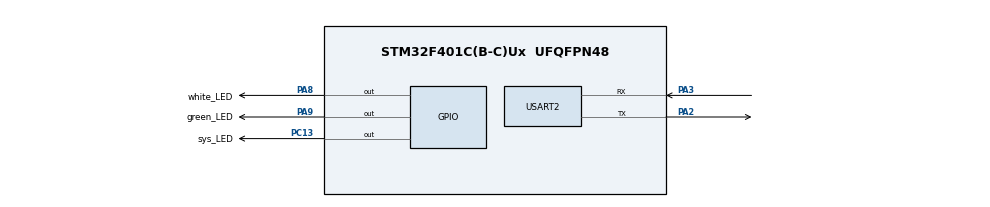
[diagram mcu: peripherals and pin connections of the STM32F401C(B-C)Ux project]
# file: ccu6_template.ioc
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FREERTOS.INCLUDE_pcTaskGetTaskName=1
FREERTOS.INCLUDE_uxTaskGetStackHighWaterMark2=1
FREERTOS.INCLUDE_vTaskCleanUpResources=1
FREERTOS.INCLUDE_xEventGroupSetBitFromISR=1
FREERTOS.INCLUDE_xSemaphoreGetMutexHolder=1
FREERTOS.INCLUDE_xTaskAbortDelay=1
FREERTOS.INCLUDE_xTaskGetHandle=1
FREERTOS.Tasks01=defaultTask,24,128,StartDefaultTask,Default,NULL,Dynamic,NULL,NULL
Mcu.Family=STM32F4
Mcu.Name=STM32F401C(B-C)Ux
Mcu.Package=UFQFPN48
NVIC.PriorityGroup=NVIC_PRIORITYGROUP_4
NVIC.TIM1_TRG_COM_TIM11_IRQn=true\:15\:0\:false\:false\:true\:false\:false\:true\:true
NVIC.TimeBase=TIM1_TRG_COM_TIM11_IRQn
NVIC.TimeBaseIP=TIM11
NVIC.USART2_IRQn=true\:5\:0\:false\:false\:true\:true\:true\:true\:true
PA13.Mode=Serial_Wire
PA13.Signal=SYS_JTMS-SWDIO
PA14.Mode=Serial_Wire
PA14.Signal=SYS_JTCK-SWCLK
PA2.Mode=Asynchronous
PA2.Signal=USART2_TX
PA3.Mode=Asynchronous
PA3.Signal=USART2_RX
PA8.GPIO_Label=white_LED
PA8.GPIO_ModeDefaultOutputPP=GPIO_MODE_OUTPUT_OD
PA8.GPIO_PuPd=GPIO_NOPULL
PA8.GPIO_Speed=GPIO_SPEED_FREQ_HIGH
PA8.PinState=GPIO_PIN_SET
PA8.Signal=GPIO_Output
PA9.GPIO_Label=green_LED
PA9.GPIO_ModeDefaultOutputPP=GPIO_MODE_OUTPUT_OD
PA9.GPIO_PuPd=GPIO_NOPULL
PA9.GPIO_Speed=GPIO_SPEED_FREQ_VERY_HIGH
PA9.PinState=GPIO_PIN_SET
PA9.Signal=GPIO_Output
PC13-ANTI_TAMP.GPIO_Label=sys_LED
PC13-ANTI_TAMP.GPIO_ModeDefaultOutputPP=GPIO_MODE_OUTPUT_OD
PC13-ANTI_TAMP.GPIO_PuPd=GPIO_NOPULL
PC13-ANTI_TAMP.PinState=GPIO_PIN_SET
PC13-ANTI_TAMP.Signal=GPIO_Output
PC14-OSC32_IN.Mode=LSE-External-Oscillator
PC14-OSC32_IN.Signal=RCC_OSC32_IN
PC15-OSC32_OUT.Mode=LSE-External-Oscillator
PC15-OSC32_OUT.Signal=RCC_OSC32_OUT
PH0\ -\ OSC_IN.Mode=HSE-External-Oscillator
PH0\ -\ OSC_IN.Signal=RCC_OSC_IN
PH1\ -\ OSC_OUT.Mode=HSE-External-Oscillator
PH1\ -\ OSC_OUT.Signal=RCC_OSC_OUT
ProjectManager.HeapSize=0x200
ProjectManager.StackSize=0x400
ProjectManager.TargetToolchain=MDK-ARM V5.32
RCC.48MHZClocksFreq_Value=42000000
RCC.AHBFreq_Value=84000000
RCC.APB1CLKDivider=RCC_HCLK_DIV2
RCC.APB1Freq_Value=42000000
RCC.APB1TimFreq_Value=84000000
RCC.APB2Freq_Value=84000000
RCC.APB2TimFreq_Value=84000000
RCC.CortexFreq_Value=84000000
RCC.HCLKFreq_Value=84000000
RCC.HSE_VALUE=25000000
RCC.HSI_VALUE=16000000
RCC.PLLM=25
RCC.PLLN=168
RCC.PLLSourceVirtual=RCC_PLLSOURCE_HSE
RCC.SYSCLKFreq_VALUE=84000000
RCC.SYSCLKSource=RCC_SYSCLKSOURCE_PLLCLK
RCC.VCOOutputFreq_Value=168000000
USART2.VirtualMode=VM_ASYNC
VP_FREERTOS_VS_CMSIS_V2.Mode=CMSIS_V2
VP_SYS_VS_tim11.Mode=TIM11
board=custom

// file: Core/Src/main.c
/* USER CODE BEGIN Header */
/**
  ******************************************************************************
  * @file           : main.c
  * @brief          : Main program body
  ******************************************************************************
  * @attention
  *
  * Copyright (c) 2025 STMicroelectronics.
  * All rights reserved.
  *
  * This software is licensed under terms that can be found in the LICENSE file
  * in the root directory of this software component.
  * If no LICENSE file comes with this software, it is provided AS-IS.
  *
  ******************************************************************************
  */
  /* USER CODE END Header */
  /* Includes ------------------------------------------------------------------*/
#include "main.h"

void SystemClock_Config (void);
void MX_FREERTOS_Init (void);

int main (void)
{

  /* MCU Configuration--------------------------------------------------------*/

  /* Reset of all peripherals, Initializes the Flash interface and the Systick. */
  HAL_Init ( );

  /* Configure the system clock */
  SystemClock_Config ( );

  /* Initialize all configured peripherals */
  MX_GPIO_Init ( );
  MX_USART2_UART_Init ( );

  /* Init scheduler */
  osKernelInitialize ( );

  /* Call init function for freertos objects (in cmsis_os2.c) */
  MX_FREERTOS_Init ( );

  /* Start scheduler */
  osKernelStart ( );

  /* We should never get here as control is now taken by the scheduler */

  /* Infinite loop */
  while (1)
  {

  }
}

void SystemClock_Config (void)
{
  LL_FLASH_SetLatency (LL_FLASH_LATENCY_2);
  while (LL_FLASH_GetLatency ( ) != LL_FLASH_LATENCY_2)
  {
  }
  LL_PWR_SetRegulVoltageScaling (LL_PWR_REGU_VOLTAGE_SCALE2);
  LL_RCC_HSE_Enable ( );

  /* Wait till HSE is ready */
  while (LL_RCC_HSE_IsReady ( ) != 1)
  {

  }
  LL_RCC_PLL_ConfigDomain_SYS (LL_RCC_PLLSOURCE_HSE , LL_RCC_PLLM_DIV_25 , 168 , LL_RCC_PLLP_DIV_2);
  LL_RCC_PLL_Enable ( );

  /* Wait till PLL is ready */
  while (LL_RCC_PLL_IsReady ( ) != 1)
  {

  }
  while (LL_PWR_IsActiveFlag_VOS ( ) == 0)
  {
  }
  LL_RCC_SetAHBPrescaler (LL_RCC_SYSCLK_DIV_1);
  LL_RCC_SetAPB1Prescaler (LL_RCC_APB1_DIV_2);
  LL_RCC_SetAPB2Prescaler (LL_RCC_APB2_DIV_1);
  LL_RCC_SetSysClkSource (LL_RCC_SYS_CLKSOURCE_PLL);

  /* Wait till System clock is ready */
  while (LL_RCC_GetSysClkSource ( ) != LL_RCC_SYS_CLKSOURCE_STATUS_PLL)
  {

  }
  LL_SetSystemCoreClock (84000000);

  /* Update the time base */
  if (HAL_InitTick (TICK_INT_PRIORITY) != HAL_OK)
  {
    Error_Handler ( );
  }
  LL_RCC_SetTIMPrescaler (LL_RCC_TIM_PRESCALER_TWICE);
}

void HAL_TIM_PeriodElapsedCallback (TIM_HandleTypeDef * htim)
{
  if (htim->Instance == TIM11)
  {
    HAL_IncTick ( );
  }
}

void Error_Handler (void)
{
  /* USER CODE BEGIN Error_Handler_Debug */
  /* User can add his own implementation to report the HAL error return state */
  __disable_irq ( );
  while (1)
  {
    SYS_LED_TOGGLE ( );
  }
  /* USER CODE END Error_Handler_Debug */
}

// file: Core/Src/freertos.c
/* USER CODE BEGIN Header */
/**
  ******************************************************************************
  * File Name          : freertos.c
  * Description        : Code for freertos applications
  ******************************************************************************
  * @attention
  *
  * Copyright (c) 2025 STMicroelectronics.
  * All rights reserved.
  *
  * This software is licensed under terms that can be found in the LICENSE file
  * in the root directory of this software component.
  * If no LICENSE file comes with this software, it is provided AS-IS.
  *
  ******************************************************************************
  */
  /* USER CODE END Header */

  /* Includes ------------------------------------------------------------------*/
#include "FreeRTOS.h"
#include "task.h"
#include "main.h"
#include "cmsis_os.h"

/* Definitions for defaultTask */
osThreadId_t defaultTaskHandle;
const osThreadAttr_t defaultTask_attributes = {
  .name = "defaultTask",
  .stack_size = 128 * 4,
  .priority = (osPriority_t) osPriorityNormal,
};

void StartDefaultTask (void * argument);

void MX_FREERTOS_Init (void); /* (MISRA C 2004 rule 8.1) */

void MX_FREERTOS_Init (void)
{

  /* Create the thread(s) */
  /* creation of defaultTask */
  defaultTaskHandle = osThreadNew (StartDefaultTask , NULL , &defaultTask_attributes);

}

void StartDefaultTask (void * argument)
{
  /* USER CODE BEGIN StartDefaultTask */
  /* Infinite loop */
  for (;;)
  {

    printf ("system frequency=%dMHz\n" , SystemCoreClock / 1000000);
    GREEN_LED_TOGGLE ( );
    WHITE_LED_TOGGLE ( );
    //任务延时
    vTaskDelay (pdMS_TO_TICKS (1000));

    GREEN_LED_TOGGLE ( );
    WHITE_LED_TOGGLE ( );

    printf ("freeRTOS alredy running!\r\n");
    //删除默认任务
    vTaskDelete (NULL);

  }
  /* USER CODE END StartDefaultTask */
}
